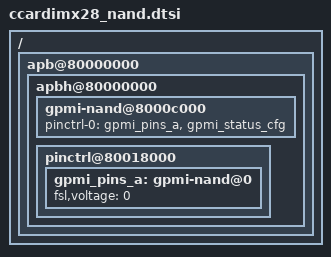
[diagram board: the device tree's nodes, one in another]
/*
 * Copyright 2013 Digi International, Inc.
 *
 * The code contained herein is licensed under the GNU General Public
 * License. You may obtain a copy of the GNU General Public License
 * Version 2 or later at the following locations:
 *
 * http://www.opensource.org/licenses/gpl-license.html
 * http://www.gnu.org/copyleft/gpl.html
 */

/ {
	apb@80000000 {
		apbh@80000000 {
			gpmi-nand@8000c000 {
				pinctrl-names = "default";
				pinctrl-0 = <&gpmi_pins_a &gpmi_status_cfg>;
				status = "okay";
			};
			pinctrl@80018000 {
				pinctrl-names = "default";

				/* NAND powered at 1.8V */
				gpmi_pins_a: gpmi-nand@0 {
					fsl,voltage = <0>;
				};
			};
		};
	};
};
